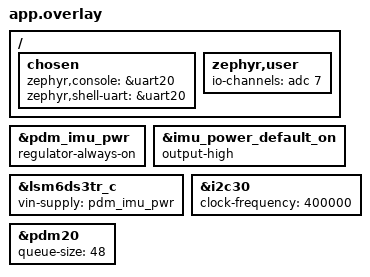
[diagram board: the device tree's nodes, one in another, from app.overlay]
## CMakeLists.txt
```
# SPDX-License-Identifier: Apache-2.0

cmake_minimum_required(VERSION 3.20.0)

set(DTC_OVERLAY_FILE ${CMAKE_CURRENT_SOURCE_DIR}/app.overlay CACHE STRING "" FORCE)

find_package(Zephyr REQUIRED HINTS $ENV{ZEPHYR_BASE})
project(archeryaimtrace-serial)

target_sources(app PRIVATE src/main.c)
target_link_libraries(app PRIVATE m)

zephyr_get(OPENFLOAT_MOUNT)
if(NOT DEFINED OPENFLOAT_MOUNT)
  set(OPENFLOAT_MOUNT "legacy-x90")
endif()
set(OPENFLOAT_MOUNT "${OPENFLOAT_MOUNT}" CACHE STRING "Raw IMU mounting profile" FORCE)
set_property(CACHE OPENFLOAT_MOUNT PROPERTY STRINGS
  legacy-x90 legacy-x90-inverted left-side-usb-string)
if(OPENFLOAT_MOUNT STREQUAL "legacy-x90")
  set(OPENFLOAT_MOUNT_DEFINE OF_MOUNT_LEGACY_X90)
elseif(OPENFLOAT_MOUNT STREQUAL "legacy-x90-inverted")
  set(OPENFLOAT_MOUNT_DEFINE OF_MOUNT_LEGACY_X90_INVERTED)
elseif(OPENFLOAT_MOUNT STREQUAL "left-side-usb-string")
  set(OPENFLOAT_MOUNT_DEFINE OF_MOUNT_LEFT_USB_STRING)
else()
  message(FATAL_ERROR "Unknown OPENFLOAT_MOUNT: ${OPENFLOAT_MOUNT}")
endif()
target_compile_definitions(app PRIVATE OPENFLOAT_MOUNT=${OPENFLOAT_MOUNT_DEFINE})
message(STATUS "ArcheryAimTrace mounting profile: ${OPENFLOAT_MOUNT}")
```

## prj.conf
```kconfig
# Battery-safe default: the XIAO nRF54L15 v1.0 can fail to boot from battery
# when the UART console is enabled. Use prj_uart.conf as an overlay when USB
# serial logs are needed for bench debugging.
CONFIG_SERIAL=n
CONFIG_PRINTK=n
CONFIG_CONSOLE=n
CONFIG_UART_CONSOLE=n
CONFIG_STDOUT_CONSOLE=n
CONFIG_I2C=y
CONFIG_GPIO=y
CONFIG_REGULATOR=y
CONFIG_REGULATOR_FIXED=y
CONFIG_CPU_LOAD=y
CONFIG_ADC=y


# Persistent shot counter: Zephyr Settings on the nRF54L RRAM via ZMS (the
# byte-alterable storage backend for this SoC; Partition Manager allocates the
# settings_storage partition automatically when SETTINGS is enabled).
CONFIG_FLASH=y
CONFIG_FLASH_MAP=y
CONFIG_ZMS=y
CONFIG_SETTINGS=y
CONFIG_SETTINGS_ZMS=y

CONFIG_MAIN_STACK_SIZE=16384
CONFIG_SYSTEM_WORKQUEUE_STACK_SIZE=4096
CONFIG_MPSL_WORK_STACK_SIZE=4096
CONFIG_BT=y
CONFIG_BT_PERIPHERAL=y
CONFIG_BT_DATA_LEN_UPDATE=y
CONFIG_BT_USER_DATA_LEN_UPDATE=y
CONFIG_BT_PHY_UPDATE=y
CONFIG_BT_USER_PHY_UPDATE=y
CONFIG_BT_DEVICE_NAME="ArcheryAimTrace"
CONFIG_BT_DEVICE_APPEARANCE=833
CONFIG_BT_CTLR_TX_PWR_PLUS_8=y
CONFIG_BT_MAX_CONN=1
CONFIG_BT_PERIPHERAL_PREF_MIN_INT=6
CONFIG_BT_PERIPHERAL_PREF_MAX_INT=6
CONFIG_BT_PERIPHERAL_PREF_LATENCY=0
CONFIG_BT_PERIPHERAL_PREF_TIMEOUT=400
CONFIG_BT_RX_STACK_SIZE=4096
CONFIG_BT_HCI_TX_STACK_SIZE=2048
CONFIG_BT_LONG_WQ_STACK_SIZE=4096
CONFIG_BT_BUF_CMD_TX_COUNT=2
CONFIG_BT_BUF_ACL_TX_COUNT=6
CONFIG_BT_BUF_ACL_TX_SIZE=217
CONFIG_BT_L2CAP_TX_BUF_COUNT=6
CONFIG_BT_BUF_ACL_RX_SIZE=217
CONFIG_BT_L2CAP_TX_MTU=212

# Deep Sleep / Power Management
CONFIG_POWEROFF=y
CONFIG_REBOOT=y

# Keep one complete offline session: 80 compact 5-second traces at 52 Hz,
# plus the ZMS journal and the shot metadata/settings records.
CONFIG_PM_PARTITION_SIZE_SETTINGS_STORAGE=0x60000

# Audio and PDM microphone drivers
CONFIG_AUDIO=y
CONFIG_AUDIO_DMIC=y
```

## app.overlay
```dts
&pdm_imu_pwr {
	regulator-always-on;
};

&imu_power_default_on {
	output-high;
};

&lsm6ds3tr_c {
	vin-supply = <&pdm_imu_pwr>;
};

&i2c30 {
	/* LSM6DS3TR-C datasheet table 7: Fast mode, max 400 kHz. */
	clock-frequency = <400000>;
};

&pdm20 {
	/* 14-sample blocks arrive at ~1143/s; default queue-size=4 starves PDM. */
	queue-size = <48>;
};

/ {
	chosen {
		zephyr,console = &uart20;
		zephyr,shell-uart = &uart20;
	};

	zephyr,user {
		io-channels = <&adc 7>;
	};
};
```

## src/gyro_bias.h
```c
/* SPDX-License-Identifier: Apache-2.0 */
#ifndef OPENFLOAT_GYRO_BIAS_H
#define OPENFLOAT_GYRO_BIAS_H
#include <math.h>
#include <stdbool.h>
#include <stdint.h>
#include <string.h>

#define OF_GYRO_CAL_SECONDS 8.0f
#define OF_GYRO_SETTLE_SECONDS 1.0f
#define OF_GYRO_WINDOW_SECONDS 0.25f
#define OF_GYRO_BIAS_LIMIT_RAD (5.0f * 0.01745329252f)
/* Engineering acceptance limits, not datasheet sensor-noise specifications.
 * Raw RMS alone does not measure the precision of the estimated DC bias.
 * Use non-overlapping block means so correlated samples are not counted as
 * independent. Keep a gross-noise guard, plus block stability, uncertainty,
 * and first/second-half agreement. No filtering of live aiming motion. */
#define OF_GYRO_NOISE_LIMIT_RAD (5.0f * 0.01745329252f)
#define OF_GYRO_BLOCK_LIMIT_DPS 0.15f
#define OF_GYRO_ERROR_LIMIT_DPS 0.025f
#define OF_GYRO_TREND_LIMIT_DPS 0.10f
#define OF_GYRO_CAL_BLOCKS 32

enum of_gyro_rejection {
	OF_GYRO_OK, OF_GYRO_TIMING, OF_GYRO_NONFINITE, OF_GYRO_RATE,
	OF_GYRO_GRAVITY, OF_GYRO_ACCEL_SHIFT, OF_GYRO_NOISE,
	OF_GYRO_SAMPLES, OF_GYRO_ACCEL_NOISE, OF_GYRO_BLOCK_NOISE,
	OF_GYRO_MEAN_ERROR, OF_GYRO_TREND, OF_GYRO_STREAM_GAP,
	OF_GYRO_FIFO_OVERFLOW, OF_GYRO_FIFO_ALIGNMENT, OF_GYRO_I2C_ERROR
};

struct of_gyro_bias {
	float bias[3];
	bool valid;
	uint8_t status; /* 0 uncalibrated, 1 collecting, 2 ready, 3 rejected */
	uint32_t count;
	float elapsed;
	float mean[3];
	float m2[3];
	float first_accel[3];
	float settling;
	float window_elapsed;
	uint32_t window_count;
	uint32_t windows;
	float accel_mean[3], accel_m2[3], gyro_mean[3];
	float block_mean[3], block_m2[3], first_half_mean[3];
	float raw_noise_dps[3], block_noise_dps[3], error_dps[3];
	uint8_t reason, axis; /* axis: 0 unspecified, 1 X, 2 Y, 3 Z */
	float observed, limit; /* diagnostics: ms, degrees/s, g, or sample count */
};

static inline void of_gyro_bias_restore(struct of_gyro_bias *cal,
		const int32_t record[4], int profile)
{
	cal->valid = false;
	cal->status = 0;
	memset(cal->bias, 0, sizeof(cal->bias));
	if (record[0] != profile) return;
	for (int i = 1; i < 4; i++) {
		if (record[i] < -5000 || record[i] > 5000) return;
	}
	for (int i = 0; i < 3; i++) cal->bias[i] = (float)record[i + 1] / 57295.779513f;
	cal->valid = true;
	cal->status = 2;
}

/* Explicit user request only: constant slow yaw cannot be distinguished from
 * bias by an IMU without a heading reference. Never learn while aiming. */
static inline void of_gyro_bias_start(struct of_gyro_bias *cal)
{
	cal->status = 1;
	cal->count = 0;
	cal->elapsed = 0;
	cal->settling = 0;
	cal->window_elapsed = 0;
	cal->window_count = 0;
	cal->windows = 0;
	cal->reason = OF_GYRO_OK;
	cal->axis = 0;
	cal->observed = cal->limit = 0;
	memset(cal->mean, 0, sizeof(cal->mean));
	memset(cal->m2, 0, sizeof(cal->m2));
	memset(cal->accel_mean, 0, sizeof(cal->accel_mean));
	memset(cal->accel_m2, 0, sizeof(cal->accel_m2));
	memset(cal->gyro_mean, 0, sizeof(cal->gyro_mean));
	memset(cal->block_mean, 0, sizeof(cal->block_mean));
	memset(cal->block_m2, 0, sizeof(cal->block_m2));
	memset(cal->first_half_mean, 0, sizeof(cal->first_half_mean));
	memset(cal->raw_noise_dps, 0, sizeof(cal->raw_noise_dps));
	memset(cal->block_noise_dps, 0, sizeof(cal->block_noise_dps));
	memset(cal->error_dps, 0, sizeof(cal->error_dps));
}

static inline uint8_t of_gyro_bias_reject(struct of_gyro_bias *cal,
		uint8_t reason, uint8_t axis, float observed, float limit)
{
	/* A failed attempt must not overwrite the last usable calibration. */
	cal->reason = reason;
	cal->axis = axis;
	cal->observed = observed;
	cal->limit = limit;
	return cal->status = 3;
}

/* Input is mounted acceleration in m/s^2 and uncorrected gyro in rad/s. */
static inline uint8_t of_gyro_bias_update(struct of_gyro_bias *cal,
		const float accel[3], const float gyro[3], float dt)
{
	if (cal->status != 1) return cal->status;
	if (!isfinite(dt) || dt <= 0 || dt > 0.02f)
		return of_gyro_bias_reject(cal, OF_GYRO_TIMING, 0, dt * 1000, 20);
	for (int i = 0; i < 3; i++) {
		if (!isfinite(accel[i]) || !isfinite(gyro[i]))
			return of_gyro_bias_reject(cal, OF_GYRO_NONFINITE, i + 1, 0, 0);
	}
	/* Startup transients must not become the reference or learned bias. */
	if (cal->settling < OF_GYRO_SETTLE_SECONDS) {
		cal->settling += dt;
		return cal->status;
	}
	cal->count++;
	cal->elapsed += dt;
	cal->window_count++;
	cal->window_elapsed += dt;
	for (int i = 0; i < 3; i++) {
		float delta = gyro[i] - cal->mean[i];
		cal->mean[i] += delta / (float)cal->count;
		cal->m2[i] += delta * (gyro[i] - cal->mean[i]);
		delta = accel[i] - cal->accel_mean[i];
		cal->accel_mean[i] += delta / (float)cal->window_count;
		cal->accel_m2[i] += delta * (accel[i] - cal->accel_mean[i]);
		cal->gyro_mean[i] += (gyro[i] - cal->gyro_mean[i]) / (float)cal->window_count;
	}
	if (cal->window_elapsed < OF_GYRO_WINDOW_SECONDS) return cal->status;
	float norm2 = 0, movement2 = 0, accel_variance = 0;
	for (int i = 0; i < 3; i++) {
		if (fabsf(cal->gyro_mean[i]) > OF_GYRO_BIAS_LIMIT_RAD)
			return of_gyro_bias_reject(cal, OF_GYRO_RATE, i + 1,
				fabsf(cal->gyro_mean[i]) * 57.295779513f, 5);
		if (cal->windows == 0) cal->first_accel[i] = cal->accel_mean[i];
		float movement = cal->accel_mean[i] - cal->first_accel[i];
		movement2 += movement * movement;
		norm2 += cal->accel_mean[i] * cal->accel_mean[i];
		accel_variance += cal->accel_m2[i] / (float)(cal->window_count - 1);
	}
	float gravity_error = fabsf(sqrtf(norm2) / 9.81f - 1.0f);
	if (gravity_error > 0.05f)
		return of_gyro_bias_reject(cal, OF_GYRO_GRAVITY, 0, gravity_error, 0.05f);
	float shift = sqrtf(movement2) / 9.81f;
	if (shift > 0.03f)
		return of_gyro_bias_reject(cal, OF_GYRO_ACCEL_SHIFT, 0, shift, 0.03f);
	float accel_noise = sqrtf(fmaxf(0, accel_variance)) / 9.81f;
	if (accel_noise > 0.05f)
		return of_gyro_bias_reject(cal, OF_GYRO_ACCEL_NOISE, 0, accel_noise, 0.05f);
	cal->windows++;
	for (int i = 0; i < 3; i++) {
		float delta = cal->gyro_mean[i] - cal->block_mean[i];
		cal->block_mean[i] += delta / (float)cal->windows;
		cal->block_m2[i] += delta * (cal->gyro_mean[i] - cal->block_mean[i]);
		if (cal->windows == OF_GYRO_CAL_BLOCKS / 2)
			cal->first_half_mean[i] = cal->block_mean[i];
	}
	cal->window_count = 0;
	cal->window_elapsed = 0;
	memset(cal->accel_mean, 0, sizeof(cal->accel_mean));
	memset(cal->accel_m2, 0, sizeof(cal->accel_m2));
	memset(cal->gyro_mean, 0, sizeof(cal->gyro_mean));
	if (cal->windows < OF_GYRO_CAL_BLOCKS) return cal->status;
	if (cal->count < 100)
		return of_gyro_bias_reject(cal, OF_GYRO_SAMPLES, 0, cal->count, 100);
	for (int i = 0; i < 3; i++) {
		float noise = sqrtf(fmaxf(0, cal->m2[i] / (float)(cal->count - 1)));
		cal->raw_noise_dps[i] = noise * 57.295779513f;
		cal->block_noise_dps[i] = sqrtf(fmaxf(0,
			cal->block_m2[i] / (float)(cal->windows - 1))) * 57.295779513f;
		cal->error_dps[i] = cal->block_noise_dps[i] / sqrtf((float)cal->windows);
	}
	for (int i = 0; i < 3; i++) {
		float noise = cal->raw_noise_dps[i] / 57.295779513f;
		if (noise > OF_GYRO_NOISE_LIMIT_RAD)
			return of_gyro_bias_reject(cal, OF_GYRO_NOISE, i + 1,
				cal->raw_noise_dps[i], 5.0f);
		if (cal->block_noise_dps[i] > OF_GYRO_BLOCK_LIMIT_DPS)
			return of_gyro_bias_reject(cal, OF_GYRO_BLOCK_NOISE, i + 1,
				cal->block_noise_dps[i], OF_GYRO_BLOCK_LIMIT_DPS);
		if (cal->error_dps[i] > OF_GYRO_ERROR_LIMIT_DPS)
			return of_gyro_bias_reject(cal, OF_GYRO_MEAN_ERROR, i + 1,
				cal->error_dps[i], OF_GYRO_ERROR_LIMIT_DPS);
		float trend = 2 * fabsf(cal->block_mean[i] - cal->first_half_mean[i]) * 57.295779513f;
		if (trend > OF_GYRO_TREND_LIMIT_DPS)
			return of_gyro_bias_reject(cal, OF_GYRO_TREND, i + 1,
				trend, OF_GYRO_TREND_LIMIT_DPS);
	}
	memcpy(cal->bias, cal->mean, sizeof(cal->bias));
	cal->observed = fmaxf(cal->error_dps[0], fmaxf(cal->error_dps[1], cal->error_dps[2]));
	cal->limit = OF_GYRO_ERROR_LIMIT_DPS;
	cal->valid = true;
	cal->status = 2;
	return cal->status;
}

static inline void of_gyro_bias_apply(const struct of_gyro_bias *cal,
		const float raw[3], float corrected[3])
{
	for (int i = 0; i < 3; i++) {
		corrected[i] = raw[i] - (cal->valid ? cal->bias[i] : 0.0f);
	}
}
#endif
```

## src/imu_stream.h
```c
/* SPDX-License-Identifier: Apache-2.0 */
#ifndef OPENFLOAT_IMU_STREAM_H
#define OPENFLOAT_IMU_STREAM_H
/* LSM6DS3TR-C I2C maximum is 400 kHz. 1666 Hz x 12 bytes leaves
 * headroom for addresses, status reads, recovery and CPU scheduling. */
#define IMU_ODR_HZ 1666
#define LSM6DSL_IMU_ODR_REG 0x08
#define SAMPLES_PER_OUTPUT 2
#define OUTPUT_DT_US ((SAMPLES_PER_OUTPUT * 1000000UL) / IMU_ODR_HZ)
#define OF_OFFLINE_TRACE_STRIDE ((IMU_ODR_HZ / SAMPLES_PER_OUTPUT + 26) / 52)
#endif
```

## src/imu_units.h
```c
/* SPDX-License-Identifier: Apache-2.0 */
#ifndef OPENFLOAT_IMU_UNITS_H
#define OPENFLOAT_IMU_UNITS_H
/* LSM6DS3TR-C datasheet, table 3: +/-2000 dps sensitivity is 70 mdps/LSB.
 * It is NOT full_scale / 32768. https://www.st.com/resource/en/datasheet/lsm6ds3tr-c.pdf */
#define OF_GYRO_2000DPS_RAD_PER_LSB (0.070f / 57.29577951308232f)
#endif
```

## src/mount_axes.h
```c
/* SPDX-License-Identifier: Apache-2.0 */
#ifndef OPENFLOAT_MOUNT_AXES_H
#define OPENFLOAT_MOUNT_AXES_H

#define OF_MOUNT_LEGACY_X90 0
#define OF_MOUNT_LEGACY_X90_INVERTED 1
#define OF_MOUNT_LEFT_USB_STRING 2

#ifndef OPENFLOAT_MOUNT
#define OPENFLOAT_MOUNT OF_MOUNT_LEGACY_X90
#endif

#if OPENFLOAT_MOUNT == OF_MOUNT_LEGACY_X90
#define OPENFLOAT_MOUNT_NAME "legacy-x90"
#elif OPENFLOAT_MOUNT == OF_MOUNT_LEGACY_X90_INVERTED
#define OPENFLOAT_MOUNT_NAME "legacy-x90-inverted"
#elif OPENFLOAT_MOUNT == OF_MOUNT_LEFT_USB_STRING
#define OPENFLOAT_MOUNT_NAME "left-side-usb-string"
#else
#error "Unsupported OPENFLOAT_MOUNT"
#endif

/*
 * Raw IMU -> fusion frame. Apply once, to both accel and gyro, before fusion.
 * Bow-aligned fusion convention: X forward, Y left, Z up.
 * The historical profiles preserve the previous firmware behavior.
 */
static inline void openfloat_mount_rotate(float *x, float *y, float *z)
{
	const float raw_y = *y;
	const float raw_z = *z;

#if OPENFLOAT_MOUNT == OF_MOUNT_LEFT_USB_STRING
	const float raw_x = *x;

	*x = raw_y;
	*y = raw_z;
	*z = raw_x;
#elif OPENFLOAT_MOUNT == OF_MOUNT_LEGACY_X90_INVERTED
	(void)x;
	*y = raw_z;
	*z = -raw_y;
#else
	(void)x;
	*y = -raw_z;
	*z = raw_y;
#endif
}

#endif
```

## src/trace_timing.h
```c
/* SPDX-License-Identifier: Apache-2.0 */
#ifndef OPENFLOAT_TRACE_TIMING_H
#define OPENFLOAT_TRACE_TIMING_H
#include <stdint.h>
#include <stddef.h>
#include <string.h>

#define OF_TRACE_HEADER_SIZE 52u
#define OF_TRACE_FORMAT 0x83u
#define OF_TRACE_PRE_SHORT 1u
#define OF_TRACE_POST_SHORT 2u
#define OF_TRACE_GAP 4u
#define OF_TRACE_BOOT_UNKNOWN 8u
#define OF_TRACE_EVENT_OUTSIDE 16u
#define OF_TRACE_SIMULATED 32u

struct of_trace_info {
    uint32_t shot_id, boot_id, period_num_us, period_den;
    uint64_t event_uptime_us;
    int32_t first_tick; /* First sample's output-tick offset from detector event. */
    uint16_t stride, count, event_index, flags, follow_ms, mount;
};

static inline uint64_t of_trace_follow_ticks(uint32_t ms, uint32_t odr, uint32_t average)
{
    uint64_t denominator = (uint64_t)average * 1000;
    return ((uint64_t)ms * odr + denominator - 1) / denominator;
}

static inline uint16_t of_trace_event_index(int32_t first_tick, uint16_t stride, uint16_t count)
{
    if (!stride || !count || first_tick > 0) return UINT16_MAX;
    uint64_t offset = (uint64_t)(-(int64_t)first_tick);
    uint64_t index = (offset + stride - 1) / stride;
    return index < count ? (uint16_t)index : UINT16_MAX;
}

static inline void of_trace_put(uint8_t *out, uint64_t value, unsigned bytes)
{
    for (unsigned i = 0; i < bytes; i++) out[i] = (uint8_t)(value >> (8 * i));
}

static inline uint32_t of_trace_crc_update(uint32_t crc, const uint8_t *bytes, size_t size)
{
    for (size_t i = 0; i < size; i++) {
        crc ^= bytes[i];
        for (unsigned bit = 0; bit < 8; bit++) crc = (crc >> 1) ^ (0xedb88320u & (0u - (crc & 1u)));
    }
    return crc;
}

static inline void of_trace_header(uint8_t out[OF_TRACE_HEADER_SIZE],
                                   const struct of_trace_info *info, const uint8_t *points)
{
    memset(out, 0, OF_TRACE_HEADER_SIZE);
    memcpy(out, "OFT3", 4);
    of_trace_put(out + 4, 3, 2);
    of_trace_put(out + 6, OF_TRACE_HEADER_SIZE, 2);
    of_trace_put(out + 8, info->shot_id, 4);
    of_trace_put(out + 12, info->boot_id, 4);
    of_trace_put(out + 16, info->period_num_us, 4);
    of_trace_put(out + 20, info->period_den, 4);
    of_trace_put(out + 24, info->event_uptime_us, 8);
    of_trace_put(out + 32, (uint32_t)info->first_tick, 4);
    of_trace_put(out + 36, info->stride, 2);
    of_trace_put(out + 38, info->count, 2);
    of_trace_put(out + 40, info->event_index, 2);
    of_trace_put(out + 42, info->flags, 2);
    of_trace_put(out + 44, info->follow_ms, 2);
    of_trace_put(out + 46, info->mount, 2);
    uint32_t crc = of_trace_crc_update(UINT32_MAX, out, 48);
    crc = of_trace_crc_update(crc, points, (size_t)info->count * 7);
    of_trace_put(out + 48, ~crc, 4);
}
#endif
```
